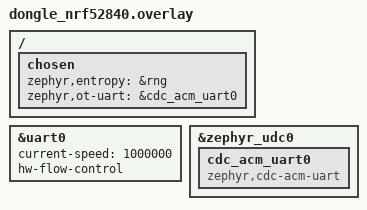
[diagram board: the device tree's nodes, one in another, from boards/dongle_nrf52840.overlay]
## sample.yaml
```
sample:
  description: Test OpenThread Co-Processor
  name: OpenThread Co-Processor sample
common:
  build_only: true
  integration_platforms:
    - connectkit_nrf52840
    - dongle_nrf52840
tests:
  sample.openthread.coprocessor: {}
  sample.openthread.coprocessor.vendor_hook:
    extra_args: OVERLAY_CONFIG=overlay-vendor_hook.conf
```

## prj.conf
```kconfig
#
# Copyright (c) 2020 Nordic Semiconductor
#
# SPDX-License-Identifier: LicenseRef-Nordic-5-Clause
#

# Set OpenThread RCP architecture
CONFIG_OPENTHREAD_COPROCESSOR=y
CONFIG_OPENTHREAD_COPROCESSOR_RCP=y

# Increase logging thread stack size due to Spinel backend needs
CONFIG_LOG_PROCESS_THREAD_STACK_SIZE=2048

# Enable OpenThread features set
CONFIG_OPENTHREAD_NORDIC_LIBRARY_MASTER=y

CONFIG_NET_L2_OPENTHREAD=y

# Generic networking options
CONFIG_NETWORKING=y

CONFIG_MBEDTLS_SHA1_C=n
CONFIG_FPU=y
```

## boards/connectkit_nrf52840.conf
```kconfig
# Enable USB transport support
CONFIG_USB_DEVICE_STACK=y
CONFIG_USB_DEVICE_REMOTE_WAKEUP=n
CONFIG_USB_CDC_ACM=y
CONFIG_USB_DEVICE_MANUFACTURER="Nordic Semiconductor ASA"
CONFIG_USB_DEVICE_PRODUCT="Thread Co-Processor"
CONFIG_USB_DEVICE_VID=0x1915
CONFIG_USB_DEVICE_PID=0x0000

CONFIG_UART_LINE_CTRL=y
```

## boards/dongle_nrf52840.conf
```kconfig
#
# Copyright (c) 2016-2023 Makerdiary
#
# SPDX-License-Identifier: Apache-2.0
#

# Enable USB transport support
CONFIG_USB_DEVICE_STACK=y
CONFIG_USB_DEVICE_REMOTE_WAKEUP=n
CONFIG_USB_CDC_ACM=y
CONFIG_USB_DEVICE_MANUFACTURER="Nordic Semiconductor ASA"
CONFIG_USB_DEVICE_PRODUCT="Thread Co-Processor"
CONFIG_USB_DEVICE_VID=0x1915
CONFIG_USB_DEVICE_PID=0x0000
CONFIG_USB_DEVICE_INITIALIZE_AT_BOOT=n

CONFIG_UART_LINE_CTRL=y
```

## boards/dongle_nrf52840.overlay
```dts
/* Copyright (c) 2020 Nordic Semiconductor ASA
 * Copyright (c) 2016-2023 Makerdiary
 *
 * SPDX-License-Identifier: LicenseRef-Nordic-5-Clause
 */

&uart0 {
    current-speed = <1000000>;
    status = "okay";
    hw-flow-control;
};

&zephyr_udc0 {
    cdc_acm_uart0: cdc_acm_uart0 {
        compatible = "zephyr,cdc-acm-uart";
    };
};

/ {
    /*
    * In some default configurations within the nRF Connect SDK,
    * e.g. on nRF52840, the chosen zephyr,entropy node is &cryptocell.
    * This devicetree overlay ensures that default is overridden wherever it
    * is set, as this application uses the RNG node for entropy exclusively.
    */
    chosen {
        zephyr,entropy = &rng;
        zephyr,ot-uart = &cdc_acm_uart0;
    };
};
```

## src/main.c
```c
/*
 * Copyright (c) 2020 Nordic Semiconductor ASA
 * Copyright (c) 2016-2023 Makerdiary
 *
 * SPDX-License-Identifier: LicenseRef-Nordic-5-Clause
 */
#include <zephyr/kernel.h>
#include <zephyr/logging/log.h>

LOG_MODULE_REGISTER(coprocessor_sample, CONFIG_OT_COPROCESSOR_LOG_LEVEL);

#define WELCOME_TEXT                                                           \
     "\n\r"                                                                 \
     "\n\r"                                                                 \
     "=========================================================\n\r"        \
     "OpenThread Coprocessor application is now running on NCS.\n\r"        \
     "=========================================================\n\r"

int main(void)
{
     LOG_INF(WELCOME_TEXT);

     return 0;
}
```

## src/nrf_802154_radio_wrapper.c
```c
/*
 * Copyright (c) 2020 Nordic Semiconductor ASA
 *
 * SPDX-License-Identifier: LicenseRef-Nordic-5-Clause
 */
#include "nrf_802154_radio_wrapper.h"
#include <nrf_802154.h>
#include <zephyr/device.h>
#include <zephyr/net/ieee802154_radio.h>

static const struct device *const radio_dev =
     DEVICE_DT_GET(DT_CHOSEN(zephyr_ieee802154));
static struct ieee802154_radio_api *radio_api;

bool nrf_802154_radio_wrapper_auto_ack_get(void)
{
     return nrf_802154_auto_ack_get();
}

void nrf_802154_radio_wrapper_auto_ack_set(bool enabled)
{
     nrf_802154_auto_ack_set(enabled);
}

uint16_t nrf_802154_radio_wrapper_hw_capabilities_get(void)
{
     __ASSERT_NO_MSG(device_is_ready(radio_dev));

     radio_api = (struct ieee802154_radio_api *)radio_dev->api;
     __ASSERT_NO_MSG(radio_api != NULL);

     return radio_api->get_capabilities(radio_dev);
}
```
